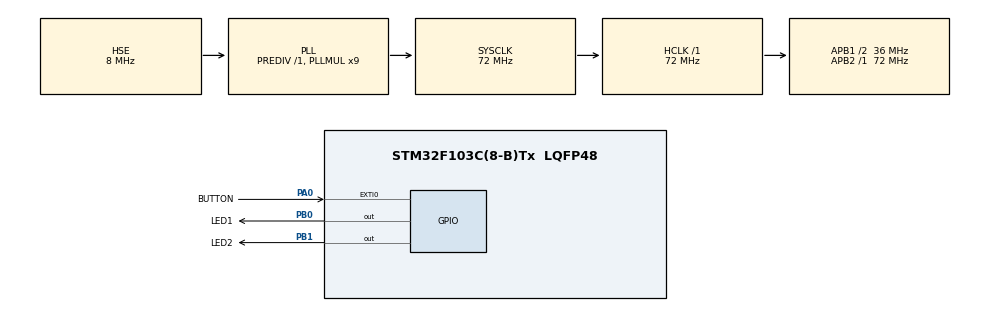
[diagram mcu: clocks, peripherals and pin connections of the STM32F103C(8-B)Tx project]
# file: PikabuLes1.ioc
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FREERTOS.BinarySemaphores01=ledOnSem,Dynamic,NULL
FREERTOS.INCLUDE_vTaskDelayUntil=1
FREERTOS.Tasks01=defaultTask,0,128,StartDefaultTask,Default,NULL,Dynamic,NULL,NULL;buttonPress,0,128,StartButtonTask,Default,NULL,Dynamic,NULL,NULL;Led1,0,128,StartLed1Task,Default,NULL,Dynamic,NULL,NULL;Led2,-3,128,StartLed2Task,Default,NULL,Dynamic,NULL,NULL
FREERTOS.configTOTAL_HEAP_SIZE=4096
Mcu.Family=STM32F1
Mcu.Name=STM32F103C(8-B)Tx
Mcu.Package=LQFP48
Mcu.UserConstants=ULONG_MAX,0xFFFFFFFF;ULONG_24,0x00FFFFFF
NVIC.EXTI0_IRQn=true\:5\:0\:false\:false\:true\:true\:true
NVIC.PriorityGroup=NVIC_PRIORITYGROUP_4
NVIC.TIM4_IRQn=true\:0\:0\:false\:false\:true\:false\:false
NVIC.TimeBase=TIM4_IRQn
NVIC.TimeBaseIP=TIM4
PA0-WKUP.GPIO_Label=BUTTON
PA0-WKUP.GPIO_ModeDefaultEXTI=GPIO_MODE_IT_RISING_FALLING
PA0-WKUP.GPIO_PuPd=GPIO_PULLUP
PA0-WKUP.Signal=GPXTI0
PA13.Mode=Serial_Wire
PA13.Signal=SYS_JTMS-SWDIO
PA14.Mode=Serial_Wire
PA14.Signal=SYS_JTCK-SWCLK
PB0.GPIO_Label=LED1
PB0.Signal=GPIO_Output
PB1.GPIO_Label=LED2
PB1.Signal=GPIO_Output
PD0-OSC_IN.Mode=HSE-External-Oscillator
PD0-OSC_IN.Signal=RCC_OSC_IN
PD1-OSC_OUT.Mode=HSE-External-Oscillator
PD1-OSC_OUT.Signal=RCC_OSC_OUT
ProjectManager.HeapSize=0x200
ProjectManager.StackSize=0x400
ProjectManager.TargetToolchain=SW4STM32
RCC.AHBFreq_Value=72000000
RCC.APB1CLKDivider=RCC_HCLK_DIV2
RCC.APB1Freq_Value=36000000
RCC.APB1TimFreq_Value=72000000
RCC.APB2Freq_Value=72000000
RCC.APB2TimFreq_Value=72000000
RCC.HCLKFreq_Value=72000000
RCC.PLLMUL=RCC_PLL_MUL9
RCC.PLLSourceVirtual=RCC_PLLSOURCE_HSE
RCC.SYSCLKFreq_VALUE=72000000
RCC.SYSCLKSource=RCC_SYSCLKSOURCE_PLLCLK
RCC.USBFreq_Value=72000000
VP_FREERTOS_VS_ENABLE.Mode=Enabled
VP_RTC_VS_RTC_Activate.Mode=RTC_Enabled
VP_RTC_VS_RTC_Calendar.Mode=RTC_Calendar
VP_SYS_VS_tim4.Mode=TIM4
board=PikabuLes1

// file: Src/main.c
/**
  ******************************************************************************
  * File Name          : main.c
  * Description        : Main program body
  ******************************************************************************
  * This notice applies to any and all portions of this file
  * that are not between comment pairs USER CODE BEGIN and
  * USER CODE END. Other portions of this file, whether
  * inserted by the user or by software development tools
  * are owned by their respective copyright owners.
  *
  * Copyright (c) 2017 STMicroelectronics International N.V.
  * All rights reserved.
  *
  * Redistribution and use in source and binary forms, with or without
  * modification, are permitted, provided that the following conditions are met:
  *
  * 1. Redistribution of source code must retain the above copyright notice,
  *    this list of conditions and the following disclaimer.
  * 2. Redistributions in binary form must reproduce the above copyright notice,
  *    this list of conditions and the following disclaimer in the documentation
  *    and/or other materials provided with the distribution.
  * 3. Neither the name of STMicroelectronics nor the names of other
  *    contributors to this software may be used to endorse or promote products
  *    derived from this software without specific written permission.
  * 4. This software, including modifications and/or derivative works of this
  *    software, must execute solely and exclusively on microcontroller or
  *    microprocessor devices manufactured by or for STMicroelectronics.
  * 5. Redistribution and use of this software other than as permitted under
  *    this license is void and will automatically terminate your rights under
  *    this license.
  *
  * THIS SOFTWARE IS PROVIDED BY STMICROELECTRONICS AND CONTRIBUTORS "AS IS"
  * AND ANY EXPRESS, IMPLIED OR STATUTORY WARRANTIES, INCLUDING, BUT NOT
  * LIMITED TO, THE IMPLIED WARRANTIES OF MERCHANTABILITY, FITNESS FOR A
  * PARTICULAR PURPOSE AND NON-INFRINGEMENT OF THIRD PARTY INTELLECTUAL PROPERTY
  * RIGHTS ARE DISCLAIMED TO THE FULLEST EXTENT PERMITTED BY LAW. IN NO EVENT
  * SHALL STMICROELECTRONICS OR CONTRIBUTORS BE LIABLE FOR ANY DIRECT, INDIRECT,
  * INCIDENTAL, SPECIAL, EXEMPLARY, OR CONSEQUENTIAL DAMAGES (INCLUDING, BUT NOT
  * LIMITED TO, PROCUREMENT OF SUBSTITUTE GOODS OR SERVICES; LOSS OF USE, DATA,
  * OR PROFITS; OR BUSINESS INTERRUPTION) HOWEVER CAUSED AND ON ANY THEORY OF
  * LIABILITY, WHETHER IN CONTRACT, STRICT LIABILITY, OR TORT (INCLUDING
  * NEGLIGENCE OR OTHERWISE) ARISING IN ANY WAY OUT OF THE USE OF THIS SOFTWARE,
  * EVEN IF ADVISED OF THE POSSIBILITY OF SUCH DAMAGE.
  *
  ******************************************************************************
  */

#include "main.h"
#include "stm32f1xx_hal.h"
#include "cmsis_os.h"

RTC_HandleTypeDef hrtc;

osThreadId defaultTaskHandle;
osThreadId buttonPressHandle;
osThreadId Led1Handle;
osThreadId Led2Handle;
osSemaphoreId ledOnSemHandle;

/* USER CODE BEGIN PV */
RTC_TimeTypeDef rtcTime;
RTC_DateTypeDef rtcDate;

/* USER CODE END PV */

void SystemClock_Config(void);
static void MX_GPIO_Init(void);
static void MX_RTC_Init(void);
void StartDefaultTask(void const * argument);
void StartButtonTask(void const * argument);
void StartLed1Task(void const * argument);
void StartLed2Task(void const * argument);

/* USER CODE BEGIN PFP */
/* Private function prototypes -----------------------------------------------*/

/* USER CODE END PFP */

int main(void) {

    /* MCU Configuration----------------------------------------------------------*/

    /* Reset of all peripherals, Initializes the Flash interface and the Systick. */
    HAL_Init();

    /* Configure the system clock */
    SystemClock_Config();

    /* Initialize all configured peripherals */
    MX_GPIO_Init();
    MX_RTC_Init();

    /* Create the semaphores(s) */
    /* definition and creation of ledOnSem */
    osSemaphoreDef(ledOnSem);
    ledOnSemHandle = osSemaphoreCreate(osSemaphore(ledOnSem), 1);

    /* Create the thread(s) */
    /* definition and creation of defaultTask */
    osThreadDef(defaultTask, StartDefaultTask, osPriorityNormal, 0, 128);
    defaultTaskHandle = osThreadCreate(osThread(defaultTask), NULL);

    /* definition and creation of buttonPress */
    osThreadDef(buttonPress, StartButtonTask, osPriorityNormal, 0, 128);
    buttonPressHandle = osThreadCreate(osThread(buttonPress), NULL);

    /* definition and creation of Led1 */
    osThreadDef(Led1, StartLed1Task, osPriorityNormal, 0, 128);
    Led1Handle = osThreadCreate(osThread(Led1), NULL);

    /* definition and creation of Led2 */
    osThreadDef(Led2, StartLed2Task, osPriorityIdle, 0, 128);
    Led2Handle = osThreadCreate(osThread(Led2), NULL);

    /* Start scheduler */
    osKernelStart();

    /* We should never get here as control is now taken by the scheduler */

    /* Infinite loop */
    while (1) {

    }

}

/** System Clock Configuration
*/
void SystemClock_Config(void) {

    RCC_OscInitTypeDef RCC_OscInitStruct;
    RCC_ClkInitTypeDef RCC_ClkInitStruct;
    RCC_PeriphCLKInitTypeDef PeriphClkInit;

    /**Initializes the CPU, AHB and APB busses clocks
    */
    RCC_OscInitStruct.OscillatorType = RCC_OSCILLATORTYPE_LSI | RCC_OSCILLATORTYPE_HSE;
    RCC_OscInitStruct.HSEState = RCC_HSE_ON;
    RCC_OscInitStruct.HSEPredivValue = RCC_HSE_PREDIV_DIV1;
    RCC_OscInitStruct.HSIState = RCC_HSI_ON;
    RCC_OscInitStruct.LSIState = RCC_LSI_ON;
    RCC_OscInitStruct.PLL.PLLState = RCC_PLL_ON;
    RCC_OscInitStruct.PLL.PLLSource = RCC_PLLSOURCE_HSE;
    RCC_OscInitStruct.PLL.PLLMUL = RCC_PLL_MUL9;

    if (HAL_RCC_OscConfig(&RCC_OscInitStruct) != HAL_OK) {
        _Error_Handler(__FILE__, __LINE__);
    }

    /**Initializes the CPU, AHB and APB busses clocks
    */
    RCC_ClkInitStruct.ClockType = RCC_CLOCKTYPE_HCLK | RCC_CLOCKTYPE_SYSCLK
                                  | RCC_CLOCKTYPE_PCLK1 | RCC_CLOCKTYPE_PCLK2;
    RCC_ClkInitStruct.SYSCLKSource = RCC_SYSCLKSOURCE_PLLCLK;
    RCC_ClkInitStruct.AHBCLKDivider = RCC_SYSCLK_DIV1;
    RCC_ClkInitStruct.APB1CLKDivider = RCC_HCLK_DIV2;
    RCC_ClkInitStruct.APB2CLKDivider = RCC_HCLK_DIV1;

    if (HAL_RCC_ClockConfig(&RCC_ClkInitStruct, FLASH_LATENCY_2) != HAL_OK) {
        _Error_Handler(__FILE__, __LINE__);
    }

    PeriphClkInit.PeriphClockSelection = RCC_PERIPHCLK_RTC;
    PeriphClkInit.RTCClockSelection = RCC_RTCCLKSOURCE_LSI;

    if (HAL_RCCEx_PeriphCLKConfig(&PeriphClkInit) != HAL_OK) {
        _Error_Handler(__FILE__, __LINE__);
    }

    /**Configure the Systick interrupt time
    */
    HAL_SYSTICK_Config(HAL_RCC_GetHCLKFreq() / 1000);

    /**Configure the Systick
    */
    HAL_SYSTICK_CLKSourceConfig(SYSTICK_CLKSOURCE_HCLK);

    /* SysTick_IRQn interrupt configuration */
    HAL_NVIC_SetPriority(SysTick_IRQn, 15, 0);
}

/* RTC init function */
static void MX_RTC_Init(void) {

    RTC_TimeTypeDef sTime;
    RTC_DateTypeDef DateToUpdate;

    /**Initialize RTC Only
    */
    hrtc.Instance = RTC;
    hrtc.Init.AsynchPrediv = RTC_AUTO_1_SECOND;
    hrtc.Init.OutPut = RTC_OUTPUTSOURCE_ALARM;

    if (HAL_RTC_Init(&hrtc) != HAL_OK) {
        _Error_Handler(__FILE__, __LINE__);
    }

    /**Initialize RTC and set the Time and Date
    */
    if (HAL_RTCEx_BKUPRead(&hrtc, RTC_BKP_DR1) != 0x32F2) {
        sTime.Hours = 0x1;
        sTime.Minutes = 0x0;
        sTime.Seconds = 0x0;

        if (HAL_RTC_SetTime(&hrtc, &sTime, RTC_FORMAT_BCD) != HAL_OK) {
            _Error_Handler(__FILE__, __LINE__);
        }

        DateToUpdate.WeekDay = RTC_WEEKDAY_MONDAY;
        DateToUpdate.Month = RTC_MONTH_JANUARY;
        DateToUpdate.Date = 0x1;
        DateToUpdate.Year = 0x0;

        if (HAL_RTC_SetDate(&hrtc, &DateToUpdate, RTC_FORMAT_BCD) != HAL_OK) {
            _Error_Handler(__FILE__, __LINE__);
        }

        HAL_RTCEx_BKUPWrite(&hrtc, RTC_BKP_DR1, 0x32F2);
    }

}

/** Configure pins as
        * Analog
        * Input
        * Output
        * EVENT_OUT
        * EXTI
*/
static void MX_GPIO_Init(void) {

    GPIO_InitTypeDef GPIO_InitStruct;

    /* GPIO Ports Clock Enable */
    __HAL_RCC_GPIOD_CLK_ENABLE();
    __HAL_RCC_GPIOA_CLK_ENABLE();
    __HAL_RCC_GPIOB_CLK_ENABLE();

    /*Configure GPIO pin Output Level */
    HAL_GPIO_WritePin(GPIOB, LED1_Pin | LED2_Pin, GPIO_PIN_RESET);

    /*Configure GPIO pin : BUTTON_Pin */
    GPIO_InitStruct.Pin = BUTTON_Pin;
    GPIO_InitStruct.Mode = GPIO_MODE_IT_RISING_FALLING;
    GPIO_InitStruct.Pull = GPIO_PULLUP;
    HAL_GPIO_Init(BUTTON_GPIO_Port, &GPIO_InitStruct);

    /*Configure GPIO pins : LED1_Pin LED2_Pin */
    GPIO_InitStruct.Pin = LED1_Pin | LED2_Pin;
    GPIO_InitStruct.Mode = GPIO_MODE_OUTPUT_PP;
    GPIO_InitStruct.Speed = GPIO_SPEED_FREQ_LOW;
    HAL_GPIO_Init(GPIOB, &GPIO_InitStruct);

    /* EXTI interrupt init*/
    HAL_NVIC_SetPriority(EXTI0_IRQn, 5, 0);
    HAL_NVIC_EnableIRQ(EXTI0_IRQn);

}

/* StartDefaultTask function */
void StartDefaultTask(void const * argument) {

    /* USER CODE BEGIN 5 */
    /*****************
     * Задача по-умолчанию.
     * Я предпочитаю пихать в неё всякие рутинные
     * вещи, вроде инициальзации и сброса состояний,
     * опроса с равными промежутками и прочее.
     *
     * Например, сейчас я сделал запуск задачи раз в
     * секунду, и запрашиваю текущее время и дату
     *****************/

    TickType_t xLastWakeTime;
    const TickType_t xFrequency = 1000;
    xLastWakeTime = xTaskGetTickCount();

    for (;;) {
        // Тут можно запускать какие-то действия
        HAL_RTC_GetTime(&hrtc, &rtcTime, RTC_FORMAT_BCD);
        HAL_RTC_GetDate(&hrtc, &rtcDate, RTC_FORMAT_BCD);

        // Благодаря этой функции, задача будет
        // уходить на новый круг в равные промежутки
        // времени.
        vTaskDelayUntil(&xLastWakeTime, xFrequency);
    }

    /* USER CODE END 5 */
}

/* StartButtonTask function */
void StartButtonTask(void const * argument) {
    /* USER CODE BEGIN StartButtonTask */
    // Внутри этой функции мы создадим отдельную переменную
    // для хранения состояния кнопки

    uint32_t notifyState = 0x00;

    for (;;) {
        xTaskNotifyWait(0x00,              /* Не очищать никакие биты на входе в функцию*/
                        ULONG_MAX,         /* Очищать все биты состояния на выходе из функции*/
                        &notifyState,      /* Состояние уведомлений извне */
                        ULONG_MAX);        /* Ожидаем нажатия кнопки до бесконечности */

        if ((notifyState & BUTTON_PRESSED) == BUTTON_PRESSED) {
            // Если кнопка нажата, то перехватим семафор
            // и зажгём оба светодиода
            // Ждём ограниченное время, иначе при нескольких
            // нажатиях подряд можем зависнуть тут навсегда
            if (xSemaphoreTake(ledOnSemHandle, 1000) == pdTRUE) {
                HAL_GPIO_WritePin(LED1_GPIO_Port, LED1_Pin, GPIO_PIN_SET);
                HAL_GPIO_WritePin(LED2_GPIO_Port, LED2_Pin, GPIO_PIN_SET);
            } else {
                // Если, вдруг, не удалось перехватить семафор,
                // Не делаем ничего, возвращаемся в состояние ожидания.
                // Даже если кнопка будет нажата, ничего меняться не будет!
                // Это наихудший вариант, если вдруг нам не удастся
                // выхватить семафор за 1000.
                //
                // ТАКИЕ ВЕЩИ НАДО ВСЕГДА УЧИТЫВАТЬ!!!
            }

        } else if ((notifyState & BUTTON_RELEASED) == BUTTON_RELEASED) {
            // Если кнопка отжата, то погасим оба светодиода
            // и отдадим семафор
            HAL_GPIO_WritePin(LED1_GPIO_Port, LED1_Pin, GPIO_PIN_RESET);
            HAL_GPIO_WritePin(LED2_GPIO_Port, LED2_Pin, GPIO_PIN_RESET);
            xSemaphoreGive(ledOnSemHandle);
        }

        /**
         * ВНИМАНИЕ!
         *
         * Вообще, так делать, конечно, плохо. В таком простом случае,
         * всё будет хорошо. Но в сложных программах нельзя допускать
         * ситуацию, когда кто-то перехватывает семафор и уходит
         * в бесконечный сон.
         */
    }

    /* USER CODE END StartButtonTask */
}

/* StartLed1Task function */
void StartLed1Task(void const * argument) {
    /* USER CODE BEGIN StartLed1Task */
    for (;;) {
        // Ждём до бесконечности, пока не сможем перехватить семафор
        if (xSemaphoreTake(ledOnSemHandle, ULONG_MAX) == pdTRUE) {
            // Когда семафор наш, зажигаем светодиод
            HAL_GPIO_WritePin(LED1_GPIO_Port, LED1_Pin, GPIO_PIN_SET);

            // Разблокирем задачу на 0,5 секунды, чтобы остальные
            // задачи могли куртиться дальше
            vTaskDelay(500);

            // Гасим светодиод
            HAL_GPIO_WritePin(LED1_GPIO_Port, LED1_Pin, GPIO_PIN_RESET);

            // Освобождаем семафор, чтобы другие могли его взять
            xSemaphoreGive(ledOnSemHandle);
        }

        // Разблокируем задачу на 0,5 секунды, чтобы остальные
        // могли работать дальше и у них была возможность
        // перехватить семафор себе
        vTaskDelay(500);
    }

    /* USER CODE END StartLed1Task */
}

/* StartLed2Task function */
void StartLed2Task(void const * argument) {
    /* USER CODE BEGIN StartLed2Task */
    for (;;) {
        if (xSemaphoreTake(ledOnSemHandle, ULONG_MAX) == pdTRUE) {
            HAL_GPIO_WritePin(LED2_GPIO_Port, LED2_Pin, GPIO_PIN_SET);
            vTaskDelay(500);
            HAL_GPIO_WritePin(LED2_GPIO_Port, LED2_Pin, GPIO_PIN_RESET);
            xSemaphoreGive(ledOnSemHandle);
        }

        vTaskDelay(500);
    }

    /* USER CODE END StartLed2Task */
}

void HAL_TIM_PeriodElapsedCallback(TIM_HandleTypeDef *htim) {
    if (htim->Instance == TIM4) {
        HAL_IncTick();
    }

}

void _Error_Handler(char * file, int line) {
    while (1) {
    }
}

/************************ (C) COPYRIGHT STMicroelectronics *****END OF FILE****/
